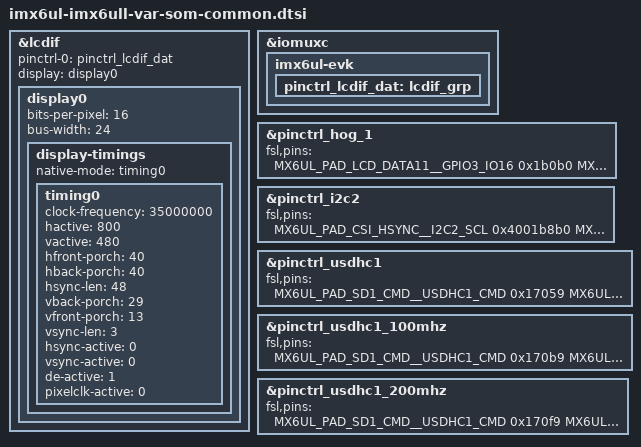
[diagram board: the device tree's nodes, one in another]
#include <dt-bindings/input/input.h>
#include "imx6ul-imx6ull-var-dart-common.dtsi"

&lcdif {
	pinctrl-names = "default";
	pinctrl-0 = <&pinctrl_lcdif_dat>;
	display = <&display0>;
	status = "okay";

	display0: display0 {
		bits-per-pixel = <16>;
		bus-width = <24>;

		display-timings {
			native-mode = <&timing0>;
			timing0: timing0 {
				clock-frequency =<35000000>;
				hactive = <800>;
				vactive = <480>;
				hfront-porch = <40>;
				hback-porch = <40>;
				hsync-len = <48>;
				vback-porch = <29>;
				vfront-porch = <13>;
				vsync-len = <3>;
				hsync-active = <0>;
				vsync-active = <0>;
				de-active = <1>;
				pixelclk-active = <0>;
			};
		};
	};
};

&iomuxc {
	imx6ul-evk {
		pinctrl_lcdif_dat:lcdif_grp {
		};
	};
};

&pinctrl_hog_1{
	fsl,pins = <
		MX6UL_PAD_LCD_DATA11__GPIO3_IO16		0x1b0b0
		MX6UL_PAD_LCD_DATA06__GPIO3_IO11		0x1b0b0
		MX6UL_PAD_LCD_DATA20__GPIO3_IO25		0x1b0b0
		MX6UL_PAD_LCD_DATA10__GPIO3_IO15		0x1b0b0
		MX6UL_PAD_LCD_DATA07__GPIO3_IO12		0x1b0b0
		MX6UL_PAD_LCD_DATA03__GPIO3_IO08		0x1b0b0
		MX6UL_PAD_LCD_DATA04__GPIO3_IO09		0x1b0b0
		MX6UL_PAD_LCD_DATA02__GPIO3_IO07		0x1b0b0
		MX6UL_PAD_LCD_DATA12__GPIO3_IO17		0x1b0b0
		MX6UL_PAD_LCD_DATA13__GPIO3_IO18		0x1b0b0
		MX6UL_PAD_LCD_DATA14__GPIO3_IO19		0x1b0b0
		MX6UL_PAD_LCD_DATA15__GPIO3_IO20		0x1b0b0
		MX6UL_PAD_LCD_DATA18__GPIO3_IO23		0x1b0b0
		MX6UL_PAD_LCD_DATA19__GPIO3_IO24		0x1b0b0
		MX6UL_PAD_LCD_DATA22__GPIO3_IO27		0x1b0b0
		MX6UL_PAD_LCD_DATA23__GPIO3_IO28		0x1b0b0
		MX6UL_PAD_LCD_CLK__GPIO3_IO00			0x1b0b0
		MX6UL_PAD_LCD_HSYNC__GPIO3_IO02			0x1b0b0
		MX6UL_PAD_LCD_VSYNC__GPIO3_IO03			0x1b0b0
		MX6UL_PAD_LCD_DATA05__GPIO3_IO10		0x1b0b0
		MX6UL_PAD_LCD_DATA21__GPIO3_IO26		0x1b0b0
		MX6UL_PAD_LCD_DATA17__GPIO3_IO22		0x1b0b0
		MX6UL_PAD_LCD_DATA16__GPIO3_IO21		0x1b0b0
		MX6UL_PAD_LCD_ENABLE__GPIO3_IO01		0x1b0b0
		MX6UL_PAD_LCD_DATA00__GPIO3_IO05		0x1b0b0
		MX6UL_PAD_LCD_DATA08__GPIO3_IO13		0x1b0b0
		MX6UL_PAD_LCD_DATA09__GPIO3_IO14		0x1b0b0
		MX6UL_PAD_LCD_RESET__GPIO3_IO04			0x1b0b0
		MX6UL_PAD_LCD_DATA01__GPIO3_IO06		0x1b0b0
		MX6UL_PAD_CSI_DATA03__GPIO4_IO24		0x1b0b0
		MX6UL_PAD_CSI_DATA07__GPIO4_IO28		0x1b0b0
		MX6UL_PAD_UART3_CTS_B__GPIO1_IO26		0x1b0b0
		MX6UL_PAD_UART3_RTS_B__GPIO1_IO27		0x1b0b0
		MX6UL_PAD_UART3_RX_DATA__GPIO1_IO25		0x1b0b0
		MX6UL_PAD_CSI_DATA01__GPIO4_IO22		0x1b0b0
		MX6UL_PAD_CSI_DATA00__GPIO4_IO21		0x1b0b0
		MX6UL_PAD_ENET2_TX_EN__GPIO2_IO13		0x1b0b0
		MX6UL_PAD_UART5_TX_DATA__GPIO1_IO30		0x1b0b0
		MX6UL_PAD_SNVS_TAMPER3__GPIO5_IO03		0x1b0b0
		MX6UL_PAD_GPIO1_IO00__GPIO1_IO00		0x1b0b0
		MX6UL_PAD_ENET2_RX_EN__GPIO2_IO10		0x1b0b0
		MX6UL_PAD_ENET2_TX_DATA0__GPIO2_IO11		0x1b0b0
		MX6UL_PAD_SNVS_TAMPER5__GPIO5_IO05		0x1b0b0
		MX6UL_PAD_SNVS_TAMPER9__GPIO5_IO09		0x1b0b0
		MX6UL_PAD_CSI_PIXCLK__GPIO4_IO18		0x1b0b0
		MX6UL_PAD_ENET2_RX_DATA1__GPIO2_IO09		0x1b0b0
		MX6UL_PAD_ENET2_RX_DATA0__GPIO2_IO08		0x1b0b0
		MX6UL_PAD_UART3_TX_DATA__GPIO1_IO24		0x1b0b0
		MX6UL_PAD_GPIO1_IO09__GPIO1_IO09		0x1b0b0
		MX6UL_PAD_GPIO1_IO08__GPIO1_IO08		0x1b0b0
		MX6UL_PAD_GPIO1_IO01__GPIO1_IO01		0x1b0b0
		MX6UL_PAD_NAND_CE1_B__GPIO4_IO14		0x1b0b0
		MX6UL_PAD_SNVS_TAMPER1__GPIO5_IO01		0x1b0b0
		MX6UL_PAD_UART4_TX_DATA__GPIO1_IO28		0x1b0b0
		MX6UL_PAD_UART5_RX_DATA__GPIO1_IO31		0x1b0b0
		MX6UL_PAD_UART4_RX_DATA__GPIO1_IO29		0x1b0b0
		MX6UL_PAD_SNVS_TAMPER7__GPIO5_IO07		0x1b0b0
		MX6UL_PAD_CSI_MCLK__GPIO4_IO17			0x1b0b0
		MX6UL_PAD_GPIO1_IO02__GPIO1_IO02		0x1b0b0
		MX6UL_PAD_GPIO1_IO04__GPIO1_IO04		0x1b0b0
		MX6UL_PAD_SNVS_TAMPER8__GPIO5_IO08		0x1b0b0
		MX6UL_PAD_GPIO1_IO05__GPIO1_IO05		0x1b0b0
		MX6UL_PAD_CSI_DATA06__GPIO4_IO27		0x1b0b0
		MX6UL_PAD_CSI_DATA02__GPIO4_IO23		0x1b0b0
		MX6UL_PAD_BOOT_MODE1__GPIO5_IO11		0x1b0b0
		MX6UL_PAD_BOOT_MODE0__GPIO5_IO10		0x1b0b0
		MX6UL_PAD_GPIO1_IO03__GPIO1_IO03		0x1b0b0
		MX6UL_PAD_CSI_DATA04__GPIO4_IO25		0x1b0b0
		MX6UL_PAD_JTAG_MOD__GPIO1_IO10			0x1b0b0
		MX6UL_PAD_ENET2_RX_ER__GPIO2_IO15		0x1b0b0
		MX6UL_PAD_ENET2_TX_CLK__GPIO2_IO14		0x1b0b0
		MX6UL_PAD_ENET2_TX_DATA1__GPIO2_IO12		0x1b0b0
		MX6UL_PAD_CSI_DATA05__GPIO4_IO26		0x1b0b0
		MX6UL_PAD_UART1_CTS_B__GPIO1_IO18		0x1b0b0
		MX6UL_PAD_UART1_RTS_B__GPIO1_IO19		0x1b0b0

		MX6UL_PAD_GPIO1_IO03__REF_CLK_32K	0x03029	/* WLAN Slow Clock */
		MX6UL_PAD_GPIO1_IO07__ENET1_MDC		0x1b0b0
		MX6UL_PAD_GPIO1_IO06__ENET1_MDIO	0x1b0b0
	>;
};

&pinctrl_i2c2{
	fsl,pins = <
		MX6UL_PAD_CSI_HSYNC__I2C2_SCL		0x4001b8b0
		MX6UL_PAD_CSI_VSYNC__I2C2_SDA		0x4001b8b0
	>;
};

&pinctrl_usdhc1{
	fsl,pins = <
		MX6UL_PAD_SD1_CMD__USDHC1_CMD		0x17059
		MX6UL_PAD_SD1_CLK__USDHC1_CLK		0x17059
		MX6UL_PAD_SD1_DATA0__USDHC1_DATA0	0x17059
		MX6UL_PAD_SD1_DATA1__USDHC1_DATA1	0x17059
		MX6UL_PAD_SD1_DATA2__USDHC1_DATA2	0x17059
		MX6UL_PAD_SD1_DATA3__USDHC1_DATA3	0x17059
	>;
};

&pinctrl_usdhc1_100mhz{
	fsl,pins = <
		MX6UL_PAD_SD1_CMD__USDHC1_CMD		0x170b9
		MX6UL_PAD_SD1_CLK__USDHC1_CLK		0x100b9
		MX6UL_PAD_SD1_DATA0__USDHC1_DATA0	0x170b9
		MX6UL_PAD_SD1_DATA1__USDHC1_DATA1	0x170b9
		MX6UL_PAD_SD1_DATA2__USDHC1_DATA2	0x170b9
		MX6UL_PAD_SD1_DATA3__USDHC1_DATA3	0x170b9
	>;
};

&pinctrl_usdhc1_200mhz{
	fsl,pins = <
		MX6UL_PAD_SD1_CMD__USDHC1_CMD		0x170f9
		MX6UL_PAD_SD1_CLK__USDHC1_CLK		0x100f9
		MX6UL_PAD_SD1_DATA0__USDHC1_DATA0	0x170f9
		MX6UL_PAD_SD1_DATA1__USDHC1_DATA1	0x170f9
		MX6UL_PAD_SD1_DATA2__USDHC1_DATA2	0x170f9
		MX6UL_PAD_SD1_DATA3__USDHC1_DATA3	0x170f9
	>;
};

